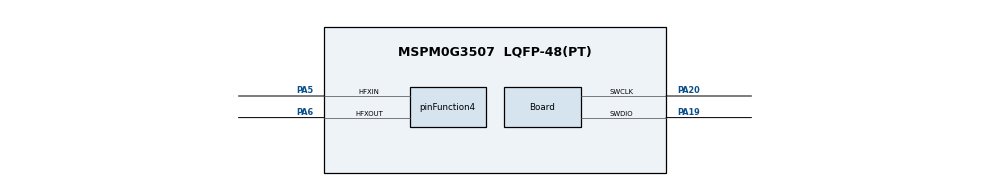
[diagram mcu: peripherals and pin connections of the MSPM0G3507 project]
/**
 * These arguments were used when this file was generated. They will be automatically applied on subsequent loads
 * via the GUI or CLI. Run CLI with '--help' for additional information on how to override these arguments.
 * @cliArgs --device "MSPM0G350X" --part "Default" --package "LQFP-48(PT)" --product "mspm0_sdk@2.02.00.05"
 * @v2CliArgs --device "MSPM0G3507" --package "LQFP-48(PT)" --product "mspm0_sdk@2.02.00.05"
 * @versions {"tool":"1.21.1+3772"}
 */
scripting.excludeFromBuild("device_linker.cmd");
scripting.excludeFromBuild("device_linker.lds");
scripting.excludeFromBuild("device.opt");
scripting.excludeFromBuild("device.cmd.genlibs");
scripting.excludeFromBuild("device.lds.genlibs");

/**
 * Import the modules used in this configuration.
 */
const SYSCTL        = scripting.addModule("/ti/driverlib/SYSCTL");
const SYSTICK       = scripting.addModule("/ti/driverlib/SYSTICK");
const ProjectConfig = scripting.addModule("/ti/project_config/ProjectConfig");

/**
 * Write custom configuration values to the imported modules.
 */
const divider6       = system.clockTree["PLL_CLK2X_DIV"];
divider6.divideValue = 4;

const divider9       = system.clockTree["UDIV"];
divider9.divideValue = 2;

const multiplier2         = system.clockTree["PLL_QDIV"];
multiplier2.multiplyValue = 4;

const mux4       = system.clockTree["EXHFMUX"];
mux4.inputSelect = "EXHFMUX_XTAL";

const mux8       = system.clockTree["HSCLKMUX"];
mux8.inputSelect = "HSCLKMUX_SYSPLL2X";

const mux12       = system.clockTree["SYSPLLMUX"];
mux12.inputSelect = "zSYSPLLMUX_HFCLK";

const pinFunction4                        = system.clockTree["HFXT"];
pinFunction4.enable                       = true;
pinFunction4.inputFreq                    = 40;
pinFunction4.peripheral.$assign           = "SYSCTL";
pinFunction4.peripheral.hfxInPin.$assign  = "PA5";
pinFunction4.peripheral.hfxOutPin.$assign = "PA6";

SYSCTL.forceDefaultClkConfig = true;
SYSCTL.clockTreeEn           = true;

const Board                       = scripting.addModule("/ti/driverlib/Board", {}, false);
Board.peripheral.$assign          = "DEBUGSS";
Board.peripheral.swclkPin.$assign = "PA20";
Board.peripheral.swdioPin.$assign = "PA19";

SYSTICK.periodEnable    = true;
SYSTICK.systickEnable   = true;
SYSTICK.interruptEnable = true;
SYSTICK.period          = 80000;

ProjectConfig.deviceSpin = "MSPM0G3507";
